# SMS0_TIFS_CBASS_0_CBASS_FW register map
Vendor: Texas Instruments
Peripheral module from a debugger description file (folder am62P).
Registers are 32-bit, read-write, reset 0x0 unless marked. A register's access mark holds for its fields unless they carry their own. Offsets are as the file gives them; lines under a group give offsets from that group; [hi:lo] are bit positions; {n}, {i} and the like mark numbered series; 'fields as' and 'values as' point back to an identical list; <NAME> marks a mode.

## SMS0_TIFS_CBASS_0_CBASS_FW
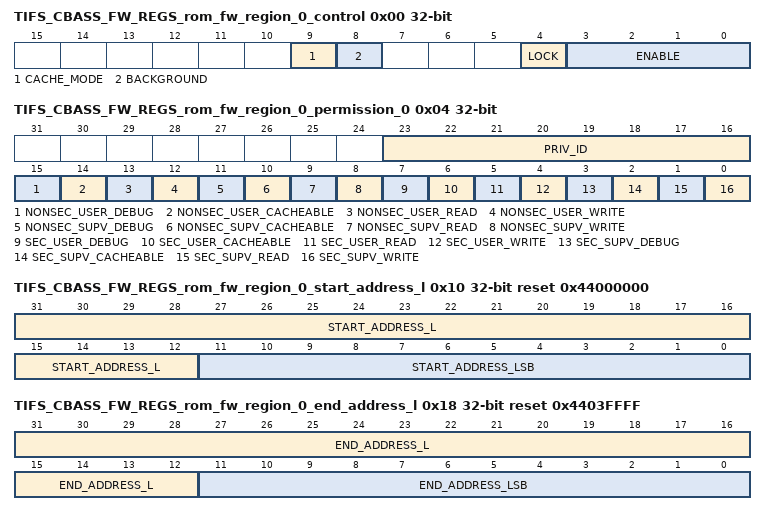
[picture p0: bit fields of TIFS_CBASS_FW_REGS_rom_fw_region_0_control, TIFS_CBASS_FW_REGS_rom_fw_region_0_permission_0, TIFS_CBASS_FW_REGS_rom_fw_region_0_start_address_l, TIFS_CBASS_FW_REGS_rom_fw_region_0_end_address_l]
0x00 TIFS_CBASS_FW_REGS_rom_fw_region_0_control access not given — The FW Region 0 Control Register defines the control fields for the target Irom.slv region 0 firewall.
  [9] CACHE_MODE rw — Cache mode for region. Set to 1 to check cache permissions. Set to 0 to ignore cache permissions.
  [8] BACKGROUND rw — Background enable for region. There can be 1 backgroun region per FW and foreground regions can have overlapping addresses only with the background region.
  [4] LOCK — Lock region. Once set region values cannot be modified. (access R/W1TS)
  [3:0] ENABLE rw — Enable region. A value of 0xA enables, others disable.
0x04 TIFS_CBASS_FW_REGS_rom_fw_region_0_permission_0 — The FW Region 0 Permission 0 Register defines the permissions for the target Irom.slv region 0 firewall.
  [23:16] PRIV_ID — Allowed privid.
  [15] NONSEC_USER_DEBUG — Non-secure user debug allowed.
  [14] NONSEC_USER_CACHEABLE — Non-secure user cacheable allowed.
  [13] NONSEC_USER_READ — Non-secure user read allowed.
  [12] NONSEC_USER_WRITE — Non-secure user write allowed.
  [11] NONSEC_SUPV_DEBUG — Non-secure supervisor debug allowed.
  [10] NONSEC_SUPV_CACHEABLE — Non-secure supervisor cacheable allowed.
  [9] NONSEC_SUPV_READ — Non-secure supervisor read allowed.
  [8] NONSEC_SUPV_WRITE — Non-secure supervisor write allowed.
  [7] SEC_USER_DEBUG — Secure user debug allowed.
  [6] SEC_USER_CACHEABLE — Secure user cacheable allowed.
  [5] SEC_USER_READ — Secure user read allowed.
  [4] SEC_USER_WRITE — Secure user write allowed.
  [3] SEC_SUPV_DEBUG — Secure supervisor debug allowed.
  [2] SEC_SUPV_CACHEABLE — Secure supervisor cacheable allowed.
  [1] SEC_SUPV_READ — Secure supervisor read allowed.
  [0] SEC_SUPV_WRITE — Secure supervisor write allowed.
0x10 TIFS_CBASS_FW_REGS_rom_fw_region_0_start_address_l access per field reset 0x44000000 — The FW Region 0 Start Address Low Register defines the start address bits 31 to 0 for the target Irom.slv region 0 firewall.
  [31:12] START_ADDRESS_L rw — Start address bits 31 to 12. Lowest 12 bits are forced to 0 as address must be 4KB aligned.
  [11:0] START_ADDRESS_LSB ro — Start address bits 11 to 0 are forced to 0 as address must be 4KB aligned.
0x14 TIFS_CBASS_FW_REGS_rom_fw_region_0_start_address_h — The FW Region 0 Start Address High Register defines the start address bits 47 to 32 for the target Irom.slv region 0 firewall.
  [15:0] START_ADDRESS_H — Start address bits 47 to 32.
0x18 TIFS_CBASS_FW_REGS_rom_fw_region_0_end_address_l access per field reset 0x4403FFFF — The FW Region 0 End Address Low Register defines the end address bits 31 to 0 to include for the target Irom.slv region 0 firewall.
  [31:12] END_ADDRESS_L rw — End address bits 31 to 12 to include in the match. Lowest 12 bits are forced to 1s as address must be 4KB aligned.
  [11:0] END_ADDRESS_LSB ro — End address bits 11 to 0 are forced to 1s as address must be 4KB aligned minus 1.
0x1C TIFS_CBASS_FW_REGS_rom_fw_region_0_end_address_h — The FW Region 0 End Address High Register defines the end address bits 47 to 32 to include for the target Irom.slv region 0 firewall.
  [15:0] END_ADDRESS_H — End address bits 47 to 32 to include in the match.
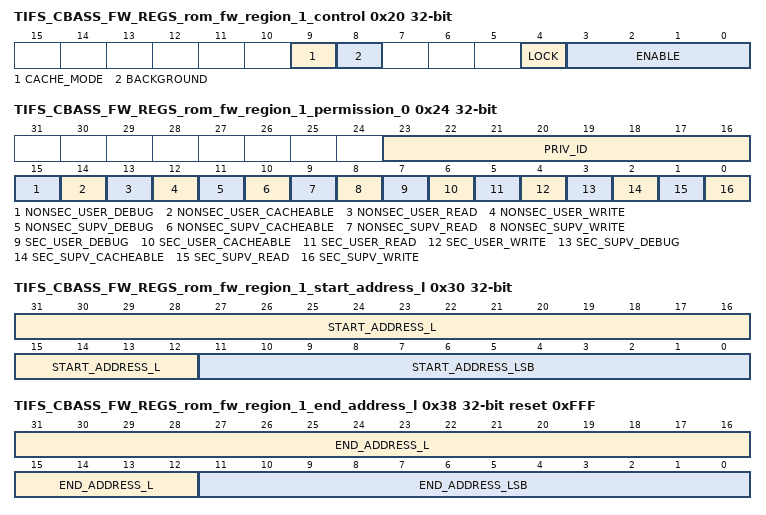
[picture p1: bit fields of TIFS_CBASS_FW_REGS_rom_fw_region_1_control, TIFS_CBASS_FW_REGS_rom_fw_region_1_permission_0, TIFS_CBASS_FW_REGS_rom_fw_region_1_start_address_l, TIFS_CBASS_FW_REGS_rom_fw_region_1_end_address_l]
0x20 TIFS_CBASS_FW_REGS_rom_fw_region_1_control access not given — The FW Region 1 Control Register defines the control fields for the target Irom.slv region 1 firewall.
  fields as TIFS_CBASS_FW_REGS_rom_fw_region_0_control
0x24 TIFS_CBASS_FW_REGS_rom_fw_region_1_permission_0 — The FW Region 1 Permission 0 Register defines the permissions for the target Irom.slv region 1 firewall.
  fields as TIFS_CBASS_FW_REGS_rom_fw_region_0_permission_0
0x30 TIFS_CBASS_FW_REGS_rom_fw_region_1_start_address_l access per field — The FW Region 1 Start Address Low Register defines the start address bits 31 to 0 for the target Irom.slv region 1 firewall.
  fields as TIFS_CBASS_FW_REGS_rom_fw_region_0_start_address_l
0x34 TIFS_CBASS_FW_REGS_rom_fw_region_1_start_address_h — The FW Region 1 Start Address High Register defines the start address bits 47 to 32 for the target Irom.slv region 1 firewall.
  [15:0] START_ADDRESS_H — Start address bits 47 to 32.
0x38 TIFS_CBASS_FW_REGS_rom_fw_region_1_end_address_l access per field reset 0xFFF — The FW Region 1 End Address Low Register defines the end address bits 31 to 0 to include for the target Irom.slv region 1 firewall.
  fields as TIFS_CBASS_FW_REGS_rom_fw_region_0_end_address_l
0x3C TIFS_CBASS_FW_REGS_rom_fw_region_1_end_address_h — The FW Region 1 End Address High Register defines the end address bits 47 to 32 to include for the target Irom.slv region 1 firewall.
  fields as TIFS_CBASS_FW_REGS_rom_fw_region_0_end_address_h
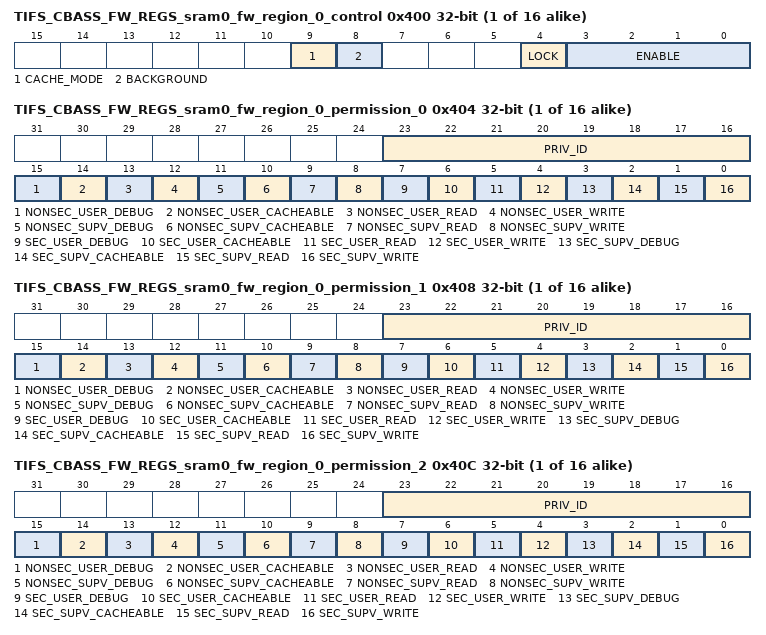
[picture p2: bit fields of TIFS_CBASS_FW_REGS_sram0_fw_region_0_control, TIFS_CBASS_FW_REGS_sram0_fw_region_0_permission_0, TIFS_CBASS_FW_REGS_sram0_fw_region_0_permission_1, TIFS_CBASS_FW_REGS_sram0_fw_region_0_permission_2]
{0x400+0x20*i} TIFS_CBASS_FW_REGS_sram0_fw_region_{i}_control access not given (i=0..15) — The FW Region {i} Control Register defines the control fields for the target Isram0.slv region {i} firewall.
  fields as TIFS_CBASS_FW_REGS_rom_fw_region_0_control
{0x404+0x20*i} TIFS_CBASS_FW_REGS_sram0_fw_region_{i}_permission_0 (i=0..15) — The FW Region {i} Permission 0 Register defines the permissions for the target Isram0.slv region {i} firewall.
  fields as TIFS_CBASS_FW_REGS_rom_fw_region_0_permission_0
{0x408+0x20*i} TIFS_CBASS_FW_REGS_sram0_fw_region_{i}_permission_1 (i=0..15) — The FW Region {i} Permission 1 Register defines the permissions for the target Isram0.slv region {i} firewall.
  fields as TIFS_CBASS_FW_REGS_rom_fw_region_0_permission_0
{0x40C+0x20*i} TIFS_CBASS_FW_REGS_sram0_fw_region_{i}_permission_2 (i=0..15) — The FW Region {i} Permission 2 Register defines the permissions for the target Isram0.slv region {i} firewall.
  fields as TIFS_CBASS_FW_REGS_rom_fw_region_0_permission_0
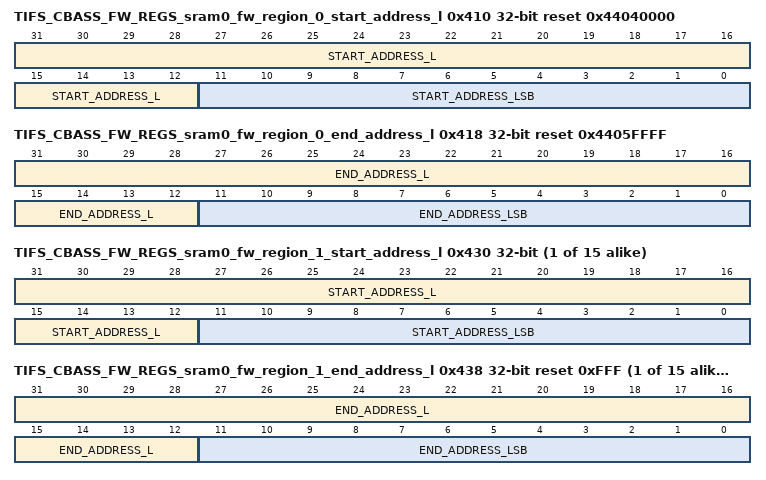
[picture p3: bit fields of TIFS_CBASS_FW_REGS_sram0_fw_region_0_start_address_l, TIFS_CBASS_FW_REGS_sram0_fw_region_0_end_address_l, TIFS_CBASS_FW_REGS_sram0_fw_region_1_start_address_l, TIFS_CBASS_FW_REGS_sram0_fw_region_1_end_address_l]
0x410 TIFS_CBASS_FW_REGS_sram0_fw_region_0_start_address_l access per field reset 0x44040000 — The FW Region 0 Start Address Low Register defines the start address bits 31 to 0 for the target Isram0.slv region 0 firewall.
  fields as TIFS_CBASS_FW_REGS_rom_fw_region_0_start_address_l
{0x414+0x20*i} TIFS_CBASS_FW_REGS_sram0_fw_region_{i}_start_address_h (i=0..15) — The FW Region {i} Start Address High Register defines the start address bits 47 to 32 for the target Isram0.slv region {i} firewall.
  [15:0] START_ADDRESS_H — Start address bits 47 to 32.
0x418 TIFS_CBASS_FW_REGS_sram0_fw_region_0_end_address_l access per field reset 0x4405FFFF — The FW Region 0 End Address Low Register defines the end address bits 31 to 0 to include for the target Isram0.slv region 0 firewall.
  fields as TIFS_CBASS_FW_REGS_rom_fw_region_0_end_address_l
{0x41C+0x20*i} TIFS_CBASS_FW_REGS_sram0_fw_region_{i}_end_address_h (i=0..15) — The FW Region {i} End Address High Register defines the end address bits 47 to 32 to include for the target Isram0.slv region {i} firewall.
  fields as TIFS_CBASS_FW_REGS_rom_fw_region_0_end_address_h
{0x410+0x20*i} TIFS_CBASS_FW_REGS_sram0_fw_region_{i}_start_address_l access per field (i=1..15) — The FW Region {i} Start Address Low Register defines the start address bits 31 to 0 for the target Isram0.slv region {i} firewall.
  fields as TIFS_CBASS_FW_REGS_rom_fw_region_0_start_address_l
{0x418+0x20*i} TIFS_CBASS_FW_REGS_sram0_fw_region_{i}_end_address_l access per field reset 0xFFF (i=1..15) — The FW Region {i} End Address Low Register defines the end address bits 31 to 0 to include for the target Isram0.slv region {i} firewall.
  fields as TIFS_CBASS_FW_REGS_rom_fw_region_0_end_address_l
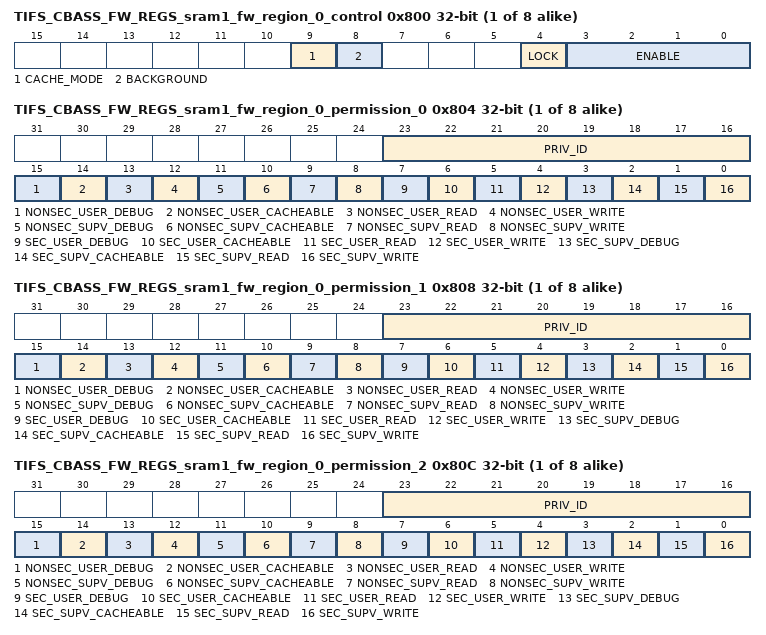
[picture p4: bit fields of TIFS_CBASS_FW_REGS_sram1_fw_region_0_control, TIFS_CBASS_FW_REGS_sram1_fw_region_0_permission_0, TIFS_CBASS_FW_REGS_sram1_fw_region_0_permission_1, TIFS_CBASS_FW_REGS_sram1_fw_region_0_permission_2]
{0x800+0x20*i} TIFS_CBASS_FW_REGS_sram1_fw_region_{i}_control access not given (i=0..7) — The FW Region {i} Control Register defines the control fields for the target Isram1.slv region {i} firewall.
  fields as TIFS_CBASS_FW_REGS_rom_fw_region_0_control
{0x804+0x20*i} TIFS_CBASS_FW_REGS_sram1_fw_region_{i}_permission_0 (i=0..7) — The FW Region {i} Permission 0 Register defines the permissions for the target Isram1.slv region {i} firewall.
  fields as TIFS_CBASS_FW_REGS_rom_fw_region_0_permission_0
{0x808+0x20*i} TIFS_CBASS_FW_REGS_sram1_fw_region_{i}_permission_1 (i=0..7) — The FW Region {i} Permission 1 Register defines the permissions for the target Isram1.slv region {i} firewall.
  fields as TIFS_CBASS_FW_REGS_rom_fw_region_0_permission_0
{0x80C+0x20*i} TIFS_CBASS_FW_REGS_sram1_fw_region_{i}_permission_2 (i=0..7) — The FW Region {i} Permission 2 Register defines the permissions for the target Isram1.slv region {i} firewall.
  fields as TIFS_CBASS_FW_REGS_rom_fw_region_0_permission_0
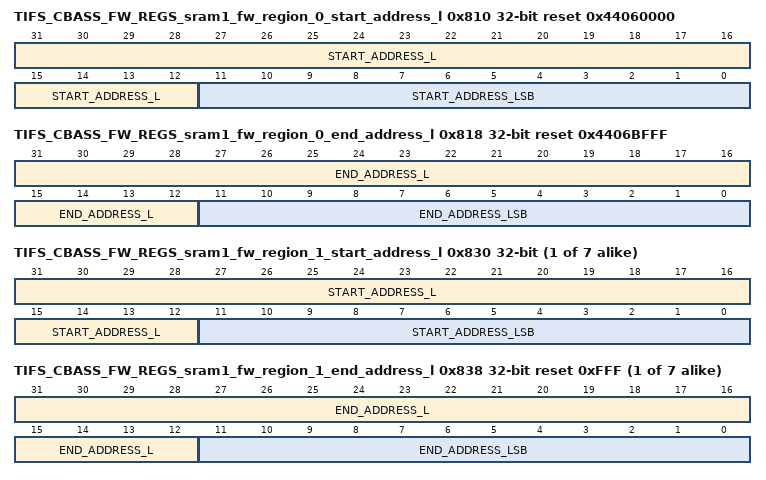
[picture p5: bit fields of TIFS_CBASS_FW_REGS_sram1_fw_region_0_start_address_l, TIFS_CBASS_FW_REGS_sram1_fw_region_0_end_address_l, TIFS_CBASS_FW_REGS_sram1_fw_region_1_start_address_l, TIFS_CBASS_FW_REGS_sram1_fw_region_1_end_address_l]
0x810 TIFS_CBASS_FW_REGS_sram1_fw_region_0_start_address_l access per field reset 0x44060000 — The FW Region 0 Start Address Low Register defines the start address bits 31 to 0 for the target Isram1.slv region 0 firewall.
  fields as TIFS_CBASS_FW_REGS_rom_fw_region_0_start_address_l
{0x814+0x20*i} TIFS_CBASS_FW_REGS_sram1_fw_region_{i}_start_address_h (i=0..7) — The FW Region {i} Start Address High Register defines the start address bits 47 to 32 for the target Isram1.slv region {i} firewall.
  [15:0] START_ADDRESS_H — Start address bits 47 to 32.
0x818 TIFS_CBASS_FW_REGS_sram1_fw_region_0_end_address_l access per field reset 0x4406BFFF — The FW Region 0 End Address Low Register defines the end address bits 31 to 0 to include for the target Isram1.slv region 0 firewall.
  fields as TIFS_CBASS_FW_REGS_rom_fw_region_0_end_address_l
{0x81C+0x20*i} TIFS_CBASS_FW_REGS_sram1_fw_region_{i}_end_address_h (i=0..7) — The FW Region {i} End Address High Register defines the end address bits 47 to 32 to include for the target Isram1.slv region {i} firewall.
  fields as TIFS_CBASS_FW_REGS_rom_fw_region_0_end_address_h
{0x810+0x20*i} TIFS_CBASS_FW_REGS_sram1_fw_region_{i}_start_address_l access per field (i=1..7) — The FW Region {i} Start Address Low Register defines the start address bits 31 to 0 for the target Isram1.slv region {i} firewall.
  fields as TIFS_CBASS_FW_REGS_rom_fw_region_0_start_address_l
{0x818+0x20*i} TIFS_CBASS_FW_REGS_sram1_fw_region_{i}_end_address_l access per field reset 0xFFF (i=1..7) — The FW Region {i} End Address Low Register defines the end address bits 31 to 0 to include for the target Isram1.slv region {i} firewall.
  fields as TIFS_CBASS_FW_REGS_rom_fw_region_0_end_address_l
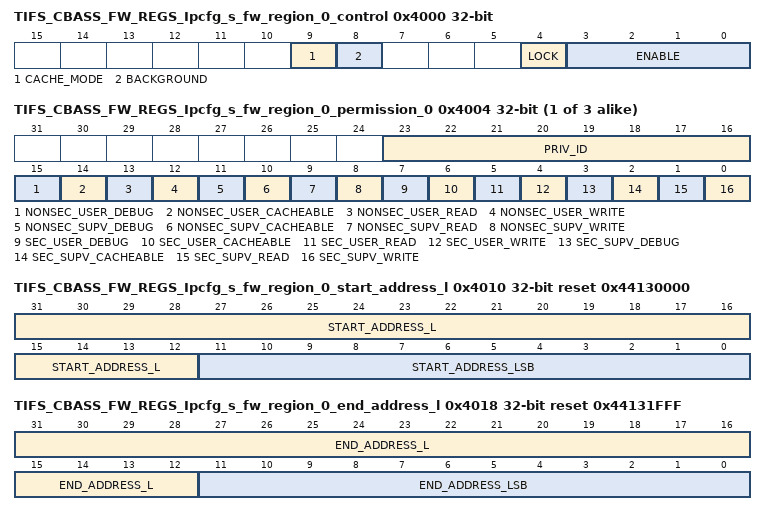
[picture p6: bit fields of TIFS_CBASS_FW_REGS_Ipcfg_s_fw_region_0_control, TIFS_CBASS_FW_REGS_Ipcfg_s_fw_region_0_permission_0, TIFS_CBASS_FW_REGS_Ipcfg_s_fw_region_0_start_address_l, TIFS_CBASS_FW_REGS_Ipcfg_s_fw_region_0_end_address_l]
0x4000 TIFS_CBASS_FW_REGS_Ipcfg_s_fw_region_0_control access not given — The FW Region 0 Control Register defines the control fields for the target Ipcfg.slv region 0 firewall.
  fields as TIFS_CBASS_FW_REGS_rom_fw_region_0_control
{0x4004+4i} TIFS_CBASS_FW_REGS_Ipcfg_s_fw_region_0_permission_{i} (i=0..2) — The FW Region 0 Permission {i} Register defines the permissions for the target Ipcfg.slv region 0 firewall.
  fields as TIFS_CBASS_FW_REGS_rom_fw_region_0_permission_0
0x4010 TIFS_CBASS_FW_REGS_Ipcfg_s_fw_region_0_start_address_l access per field reset 0x44130000 — The FW Region 0 Start Address Low Register defines the start address bits 31 to 0 for the target Ipcfg.slv region 0 firewall.
  fields as TIFS_CBASS_FW_REGS_rom_fw_region_0_start_address_l
0x4014 TIFS_CBASS_FW_REGS_Ipcfg_s_fw_region_0_start_address_h — The FW Region 0 Start Address High Register defines the start address bits 47 to 32 for the target Ipcfg.slv region 0 firewall.
  [15:0] START_ADDRESS_H — Start address bits 47 to 32.
0x4018 TIFS_CBASS_FW_REGS_Ipcfg_s_fw_region_0_end_address_l access per field reset 0x44131FFF — The FW Region 0 End Address Low Register defines the end address bits 31 to 0 to include for the target Ipcfg.slv region 0 firewall.
  fields as TIFS_CBASS_FW_REGS_rom_fw_region_0_end_address_l
0x401C TIFS_CBASS_FW_REGS_Ipcfg_s_fw_region_0_end_address_h — The FW Region 0 End Address High Register defines the end address bits 47 to 32 to include for the target Ipcfg.slv region 0 firewall.
  fields as TIFS_CBASS_FW_REGS_rom_fw_region_0_end_address_h
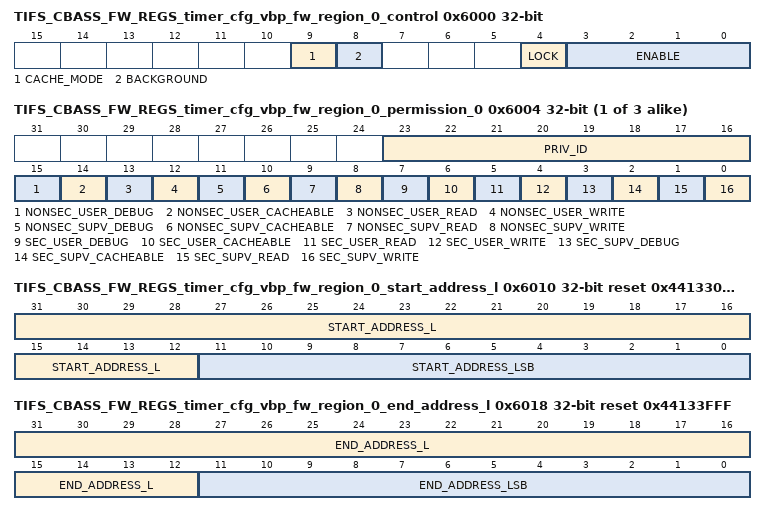
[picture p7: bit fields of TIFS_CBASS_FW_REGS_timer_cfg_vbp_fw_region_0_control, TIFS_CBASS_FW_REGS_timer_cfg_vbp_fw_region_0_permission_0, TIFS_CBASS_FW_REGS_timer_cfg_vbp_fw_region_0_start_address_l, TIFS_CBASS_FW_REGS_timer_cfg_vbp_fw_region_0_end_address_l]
0x6000 TIFS_CBASS_FW_REGS_timer_cfg_vbp_fw_region_0_control access not given — The FW Region 0 Control Register defines the control fields for the target Itimer1.timer_cfg_vbp region 0 firewall.
  fields as TIFS_CBASS_FW_REGS_rom_fw_region_0_control
{0x6004+4i} TIFS_CBASS_FW_REGS_timer_cfg_vbp_fw_region_0_permission_{i} (i=0..2) — The FW Region 0 Permission {i} Register defines the permissions for the target Itimer1.timer_cfg_vbp region 0 firewall.
  fields as TIFS_CBASS_FW_REGS_rom_fw_region_0_permission_0
0x6010 TIFS_CBASS_FW_REGS_timer_cfg_vbp_fw_region_0_start_address_l access per field reset 0x44133000 — The FW Region 0 Start Address Low Register defines the start address bits 31 to 0 for the target Itimer1.timer_cfg_vbp region 0 firewall.
  fields as TIFS_CBASS_FW_REGS_rom_fw_region_0_start_address_l
0x6014 TIFS_CBASS_FW_REGS_timer_cfg_vbp_fw_region_0_start_address_h — The FW Region 0 Start Address High Register defines the start address bits 47 to 32 for the target Itimer1.timer_cfg_vbp region 0 firewall.
  [15:0] START_ADDRESS_H — Start address bits 47 to 32.
0x6018 TIFS_CBASS_FW_REGS_timer_cfg_vbp_fw_region_0_end_address_l access per field reset 0x44133FFF — The FW Region 0 End Address Low Register defines the end address bits 31 to 0 to include for the target Itimer1.timer_cfg_vbp region 0 firewall.
  fields as TIFS_CBASS_FW_REGS_rom_fw_region_0_end_address_l
0x601C TIFS_CBASS_FW_REGS_timer_cfg_vbp_fw_region_0_end_address_h — The FW Region 0 End Address High Register defines the end address bits 47 to 32 to include for the target Itimer1.timer_cfg_vbp region 0 firewall.
  fields as TIFS_CBASS_FW_REGS_rom_fw_region_0_end_address_h
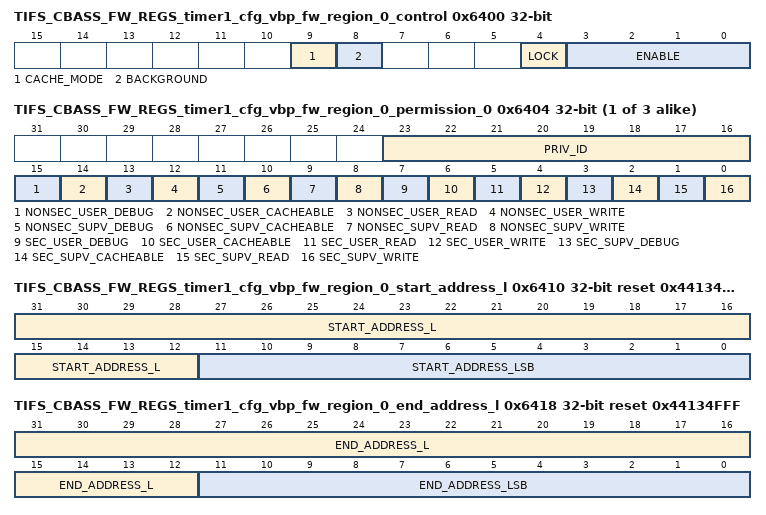
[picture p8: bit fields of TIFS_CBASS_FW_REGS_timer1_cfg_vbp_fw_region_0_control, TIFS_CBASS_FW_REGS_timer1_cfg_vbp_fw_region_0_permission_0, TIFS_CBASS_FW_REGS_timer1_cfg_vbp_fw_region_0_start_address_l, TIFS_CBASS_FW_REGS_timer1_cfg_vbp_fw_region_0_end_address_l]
0x6400 TIFS_CBASS_FW_REGS_timer1_cfg_vbp_fw_region_0_control access not given — The FW Region 0 Control Register defines the control fields for the target Itimer2.timer_cfg_vbp region 0 firewall.
  fields as TIFS_CBASS_FW_REGS_rom_fw_region_0_control
{0x6404+4i} TIFS_CBASS_FW_REGS_timer1_cfg_vbp_fw_region_0_permission_{i} (i=0..2) — The FW Region 0 Permission {i} Register defines the permissions for the target Itimer2.timer_cfg_vbp region 0 firewall.
  fields as TIFS_CBASS_FW_REGS_rom_fw_region_0_permission_0
0x6410 TIFS_CBASS_FW_REGS_timer1_cfg_vbp_fw_region_0_start_address_l access per field reset 0x44134000 — The FW Region 0 Start Address Low Register defines the start address bits 31 to 0 for the target Itimer2.timer_cfg_vbp region 0 firewall.
  fields as TIFS_CBASS_FW_REGS_rom_fw_region_0_start_address_l
0x6414 TIFS_CBASS_FW_REGS_timer1_cfg_vbp_fw_region_0_start_address_h — The FW Region 0 Start Address High Register defines the start address bits 47 to 32 for the target Itimer2.timer_cfg_vbp region 0 firewall.
  [15:0] START_ADDRESS_H — Start address bits 47 to 32.
0x6418 TIFS_CBASS_FW_REGS_timer1_cfg_vbp_fw_region_0_end_address_l access per field reset 0x44134FFF — The FW Region 0 End Address Low Register defines the end address bits 31 to 0 to include for the target Itimer2.timer_cfg_vbp region 0 firewall.
  fields as TIFS_CBASS_FW_REGS_rom_fw_region_0_end_address_l
0x641C TIFS_CBASS_FW_REGS_timer1_cfg_vbp_fw_region_0_end_address_h — The FW Region 0 End Address High Register defines the end address bits 47 to 32 to include for the target Itimer2.timer_cfg_vbp region 0 firewall.
  fields as TIFS_CBASS_FW_REGS_rom_fw_region_0_end_address_h
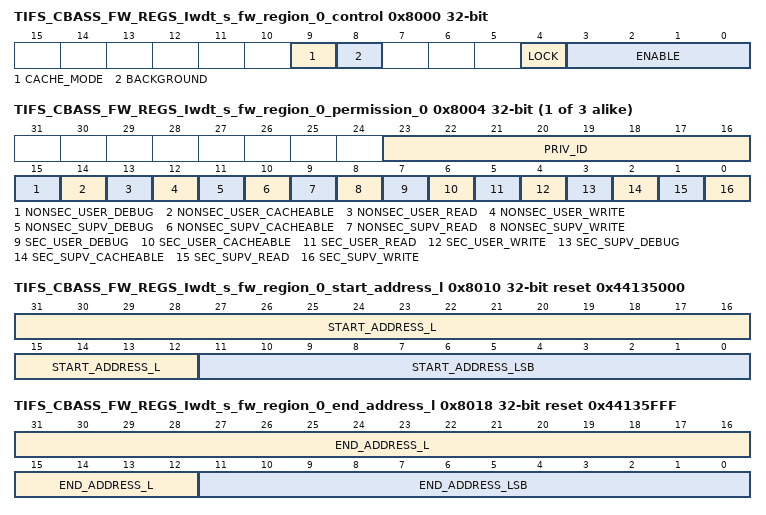
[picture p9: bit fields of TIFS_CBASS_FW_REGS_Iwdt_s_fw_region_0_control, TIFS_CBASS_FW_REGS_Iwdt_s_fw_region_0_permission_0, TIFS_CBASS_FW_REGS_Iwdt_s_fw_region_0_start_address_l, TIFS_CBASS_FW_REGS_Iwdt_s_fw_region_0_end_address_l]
0x8000 TIFS_CBASS_FW_REGS_Iwdt_s_fw_region_0_control access not given — The FW Region 0 Control Register defines the control fields for the target Iwdt.slv region 0 firewall.
  fields as TIFS_CBASS_FW_REGS_rom_fw_region_0_control
{0x8004+4i} TIFS_CBASS_FW_REGS_Iwdt_s_fw_region_0_permission_{i} (i=0..2) — The FW Region 0 Permission {i} Register defines the permissions for the target Iwdt.slv region 0 firewall.
  fields as TIFS_CBASS_FW_REGS_rom_fw_region_0_permission_0
0x8010 TIFS_CBASS_FW_REGS_Iwdt_s_fw_region_0_start_address_l access per field reset 0x44135000 — The FW Region 0 Start Address Low Register defines the start address bits 31 to 0 for the target Iwdt.slv region 0 firewall.
  fields as TIFS_CBASS_FW_REGS_rom_fw_region_0_start_address_l
0x8014 TIFS_CBASS_FW_REGS_Iwdt_s_fw_region_0_start_address_h — The FW Region 0 Start Address High Register defines the start address bits 47 to 32 for the target Iwdt.slv region 0 firewall.
  [15:0] START_ADDRESS_H — Start address bits 47 to 32.
0x8018 TIFS_CBASS_FW_REGS_Iwdt_s_fw_region_0_end_address_l access per field reset 0x44135FFF — The FW Region 0 End Address Low Register defines the end address bits 31 to 0 to include for the target Iwdt.slv region 0 firewall.
  fields as TIFS_CBASS_FW_REGS_rom_fw_region_0_end_address_l
0x801C TIFS_CBASS_FW_REGS_Iwdt_s_fw_region_0_end_address_h — The FW Region 0 End Address High Register defines the end address bits 47 to 32 to include for the target Iwdt.slv region 0 firewall.
  fields as TIFS_CBASS_FW_REGS_rom_fw_region_0_end_address_h
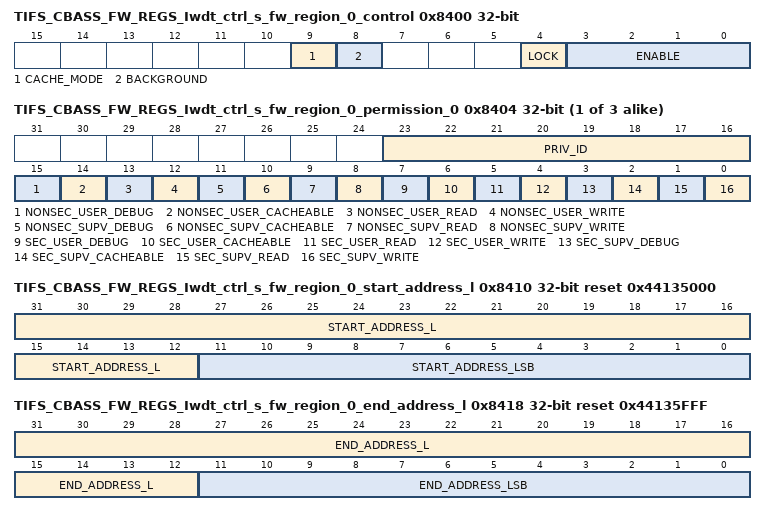
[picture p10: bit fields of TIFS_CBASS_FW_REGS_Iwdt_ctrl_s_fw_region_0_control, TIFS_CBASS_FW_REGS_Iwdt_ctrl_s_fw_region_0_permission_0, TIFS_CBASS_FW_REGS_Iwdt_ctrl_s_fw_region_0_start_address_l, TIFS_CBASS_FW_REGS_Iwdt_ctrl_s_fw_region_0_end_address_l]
0x8400 TIFS_CBASS_FW_REGS_Iwdt_ctrl_s_fw_region_0_control access not given — The FW Region 0 Control Register defines the control fields for the target Iwdt_ctrl.slv region 0 firewall.
  fields as TIFS_CBASS_FW_REGS_rom_fw_region_0_control
{0x8404+4i} TIFS_CBASS_FW_REGS_Iwdt_ctrl_s_fw_region_0_permission_{i} (i=0..2) — The FW Region 0 Permission {i} Register defines the permissions for the target Iwdt_ctrl.slv region 0 firewall.
  fields as TIFS_CBASS_FW_REGS_rom_fw_region_0_permission_0
0x8410 TIFS_CBASS_FW_REGS_Iwdt_ctrl_s_fw_region_0_start_address_l access per field reset 0x44135000 — The FW Region 0 Start Address Low Register defines the start address bits 31 to 0 for the target Iwdt_ctrl.slv region 0 firewall.
  fields as TIFS_CBASS_FW_REGS_rom_fw_region_0_start_address_l
0x8414 TIFS_CBASS_FW_REGS_Iwdt_ctrl_s_fw_region_0_start_address_h — The FW Region 0 Start Address High Register defines the start address bits 47 to 32 for the target Iwdt_ctrl.slv region 0 firewall.
  [15:0] START_ADDRESS_H — Start address bits 47 to 32.
0x8418 TIFS_CBASS_FW_REGS_Iwdt_ctrl_s_fw_region_0_end_address_l access per field reset 0x44135FFF — The FW Region 0 End Address Low Register defines the end address bits 31 to 0 to include for the target Iwdt_ctrl.slv region 0 firewall.
  fields as TIFS_CBASS_FW_REGS_rom_fw_region_0_end_address_l
0x841C TIFS_CBASS_FW_REGS_Iwdt_ctrl_s_fw_region_0_end_address_h — The FW Region 0 End Address High Register defines the end address bits 47 to 32 to include for the target Iwdt_ctrl.slv region 0 firewall.
  fields as TIFS_CBASS_FW_REGS_rom_fw_region_0_end_address_h
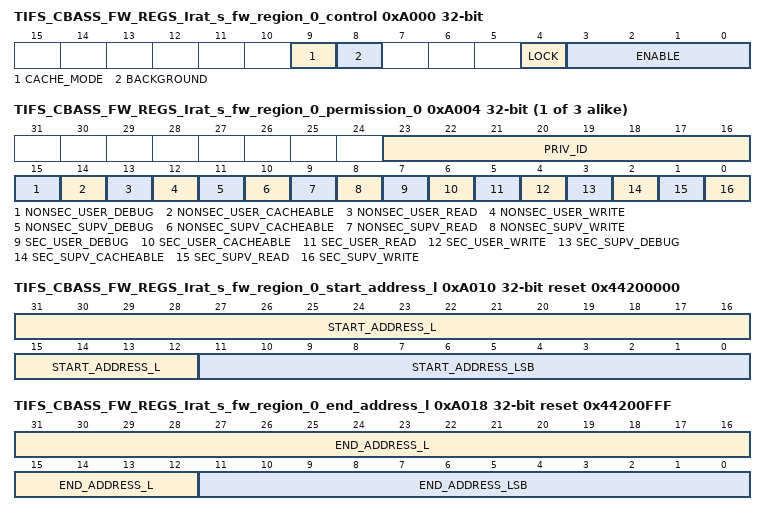
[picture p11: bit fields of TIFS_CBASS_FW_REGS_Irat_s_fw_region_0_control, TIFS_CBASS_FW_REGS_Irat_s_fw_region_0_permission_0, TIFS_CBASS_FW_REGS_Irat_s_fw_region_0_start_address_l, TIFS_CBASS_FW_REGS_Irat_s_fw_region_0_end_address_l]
0xA000 TIFS_CBASS_FW_REGS_Irat_s_fw_region_0_control access not given — The FW Region 0 Control Register defines the control fields for the target Irat.slv region 0 firewall.
  fields as TIFS_CBASS_FW_REGS_rom_fw_region_0_control
{0xA004+4i} TIFS_CBASS_FW_REGS_Irat_s_fw_region_0_permission_{i} (i=0..2) — The FW Region 0 Permission {i} Register defines the permissions for the target Irat.slv region 0 firewall.
  fields as TIFS_CBASS_FW_REGS_rom_fw_region_0_permission_0
0xA010 TIFS_CBASS_FW_REGS_Irat_s_fw_region_0_start_address_l access per field reset 0x44200000 — The FW Region 0 Start Address Low Register defines the start address bits 31 to 0 for the target Irat.slv region 0 firewall.
  fields as TIFS_CBASS_FW_REGS_rom_fw_region_0_start_address_l
0xA014 TIFS_CBASS_FW_REGS_Irat_s_fw_region_0_start_address_h — The FW Region 0 Start Address High Register defines the start address bits 47 to 32 for the target Irat.slv region 0 firewall.
  [15:0] START_ADDRESS_H — Start address bits 47 to 32.
0xA018 TIFS_CBASS_FW_REGS_Irat_s_fw_region_0_end_address_l access per field reset 0x44200FFF — The FW Region 0 End Address Low Register defines the end address bits 31 to 0 to include for the target Irat.slv region 0 firewall.
  fields as TIFS_CBASS_FW_REGS_rom_fw_region_0_end_address_l
0xA01C TIFS_CBASS_FW_REGS_Irat_s_fw_region_0_end_address_h — The FW Region 0 End Address High Register defines the end address bits 47 to 32 to include for the target Irat.slv region 0 firewall.
  fields as TIFS_CBASS_FW_REGS_rom_fw_region_0_end_address_h
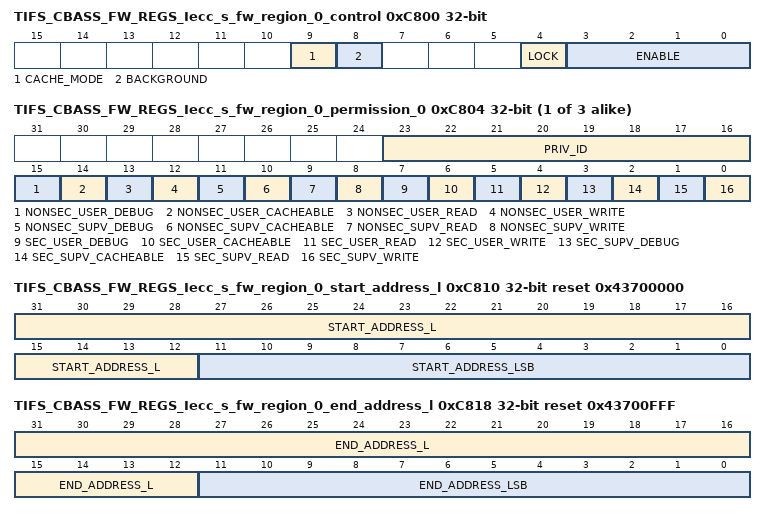
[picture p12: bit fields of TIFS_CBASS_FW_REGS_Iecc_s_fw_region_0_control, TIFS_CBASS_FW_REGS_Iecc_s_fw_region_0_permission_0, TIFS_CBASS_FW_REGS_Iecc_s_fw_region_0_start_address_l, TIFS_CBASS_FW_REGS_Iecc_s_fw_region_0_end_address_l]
0xC800 TIFS_CBASS_FW_REGS_Iecc_s_fw_region_0_control access not given — The FW Region 0 Control Register defines the control fields for the target Iecc.cfg region 0 firewall.
  fields as TIFS_CBASS_FW_REGS_rom_fw_region_0_control
{0xC804+4i} TIFS_CBASS_FW_REGS_Iecc_s_fw_region_0_permission_{i} (i=0..2) — The FW Region 0 Permission {i} Register defines the permissions for the target Iecc.cfg region 0 firewall.
  fields as TIFS_CBASS_FW_REGS_rom_fw_region_0_permission_0
0xC810 TIFS_CBASS_FW_REGS_Iecc_s_fw_region_0_start_address_l access per field reset 0x43700000 — The FW Region 0 Start Address Low Register defines the start address bits 31 to 0 for the target Iecc.cfg region 0 firewall.
  fields as TIFS_CBASS_FW_REGS_rom_fw_region_0_start_address_l
0xC814 TIFS_CBASS_FW_REGS_Iecc_s_fw_region_0_start_address_h — The FW Region 0 Start Address High Register defines the start address bits 47 to 32 for the target Iecc.cfg region 0 firewall.
  [15:0] START_ADDRESS_H — Start address bits 47 to 32.
0xC818 TIFS_CBASS_FW_REGS_Iecc_s_fw_region_0_end_address_l access per field reset 0x43700FFF — The FW Region 0 End Address Low Register defines the end address bits 31 to 0 to include for the target Iecc.cfg region 0 firewall.
  fields as TIFS_CBASS_FW_REGS_rom_fw_region_0_end_address_l
0xC81C TIFS_CBASS_FW_REGS_Iecc_s_fw_region_0_end_address_h — The FW Region 0 End Address High Register defines the end address bits 47 to 32 to include for the target Iecc.cfg region 0 firewall.
  fields as TIFS_CBASS_FW_REGS_rom_fw_region_0_end_address_h
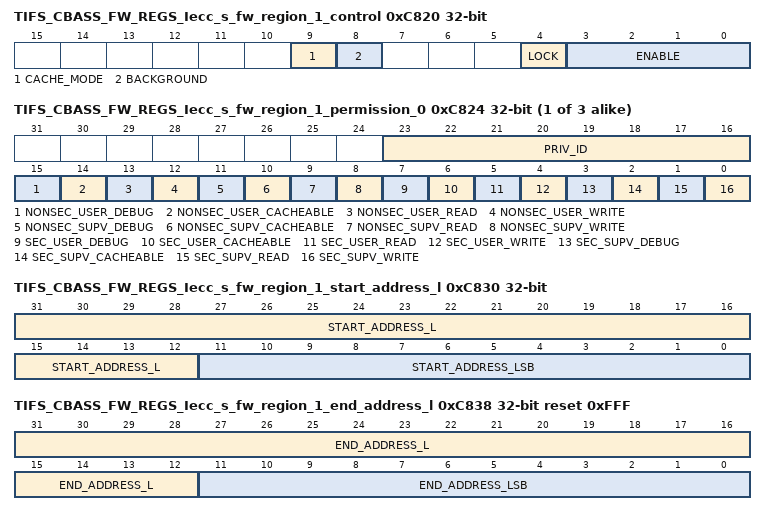
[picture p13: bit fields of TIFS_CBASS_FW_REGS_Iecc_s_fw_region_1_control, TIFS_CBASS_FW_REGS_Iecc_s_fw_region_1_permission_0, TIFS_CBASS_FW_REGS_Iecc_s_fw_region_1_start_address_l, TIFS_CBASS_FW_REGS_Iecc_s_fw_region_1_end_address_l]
0xC820 TIFS_CBASS_FW_REGS_Iecc_s_fw_region_1_control access not given — The FW Region 1 Control Register defines the control fields for the target Iecc.cfg region 1 firewall.
  fields as TIFS_CBASS_FW_REGS_rom_fw_region_0_control
{0xC824+4i} TIFS_CBASS_FW_REGS_Iecc_s_fw_region_1_permission_{i} (i=0..2) — The FW Region 1 Permission {i} Register defines the permissions for the target Iecc.cfg region 1 firewall.
  fields as TIFS_CBASS_FW_REGS_rom_fw_region_0_permission_0
0xC830 TIFS_CBASS_FW_REGS_Iecc_s_fw_region_1_start_address_l access per field — The FW Region 1 Start Address Low Register defines the start address bits 31 to 0 for the target Iecc.cfg region 1 firewall.
  fields as TIFS_CBASS_FW_REGS_rom_fw_region_0_start_address_l
0xC834 TIFS_CBASS_FW_REGS_Iecc_s_fw_region_1_start_address_h — The FW Region 1 Start Address High Register defines the start address bits 47 to 32 for the target Iecc.cfg region 1 firewall.
  [15:0] START_ADDRESS_H — Start address bits 47 to 32.
0xC838 TIFS_CBASS_FW_REGS_Iecc_s_fw_region_1_end_address_l access per field reset 0xFFF — The FW Region 1 End Address Low Register defines the end address bits 31 to 0 to include for the target Iecc.cfg region 1 firewall.
  fields as TIFS_CBASS_FW_REGS_rom_fw_region_0_end_address_l
0xC83C TIFS_CBASS_FW_REGS_Iecc_s_fw_region_1_end_address_h — The FW Region 1 End Address High Register defines the end address bits 47 to 32 to include for the target Iecc.cfg region 1 firewall.
  fields as TIFS_CBASS_FW_REGS_rom_fw_region_0_end_address_h
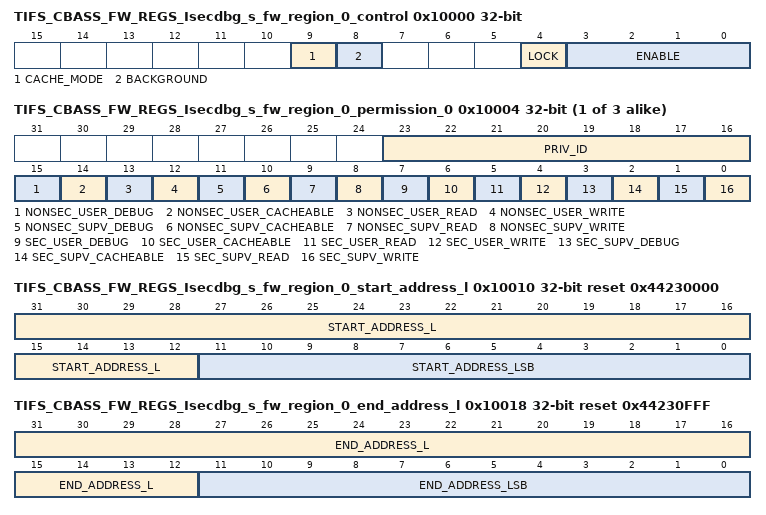
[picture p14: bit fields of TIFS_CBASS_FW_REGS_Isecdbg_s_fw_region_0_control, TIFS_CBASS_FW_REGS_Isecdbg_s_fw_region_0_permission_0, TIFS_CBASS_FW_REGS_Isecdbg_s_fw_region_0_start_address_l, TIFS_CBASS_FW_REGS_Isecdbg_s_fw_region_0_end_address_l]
0x10000 TIFS_CBASS_FW_REGS_Isecdbg_s_fw_region_0_control access not given — The FW Region 0 Control Register defines the control fields for the target Isecdbg.slv region 0 firewall.
  fields as TIFS_CBASS_FW_REGS_rom_fw_region_0_control
{0x10004+4i} TIFS_CBASS_FW_REGS_Isecdbg_s_fw_region_0_permission_{i} (i=0..2) — The FW Region 0 Permission {i} Register defines the permissions for the target Isecdbg.slv region 0 firewall.
  fields as TIFS_CBASS_FW_REGS_rom_fw_region_0_permission_0
0x10010 TIFS_CBASS_FW_REGS_Isecdbg_s_fw_region_0_start_address_l access per field reset 0x44230000 — The FW Region 0 Start Address Low Register defines the start address bits 31 to 0 for the target Isecdbg.slv region 0 firewall.
  fields as TIFS_CBASS_FW_REGS_rom_fw_region_0_start_address_l
0x10014 TIFS_CBASS_FW_REGS_Isecdbg_s_fw_region_0_start_address_h — The FW Region 0 Start Address High Register defines the start address bits 47 to 32 for the target Isecdbg.slv region 0 firewall.
  [15:0] START_ADDRESS_H — Start address bits 47 to 32.
0x10018 TIFS_CBASS_FW_REGS_Isecdbg_s_fw_region_0_end_address_l access per field reset 0x44230FFF — The FW Region 0 End Address Low Register defines the end address bits 31 to 0 to include for the target Isecdbg.slv region 0 firewall.
  fields as TIFS_CBASS_FW_REGS_rom_fw_region_0_end_address_l
0x1001C TIFS_CBASS_FW_REGS_Isecdbg_s_fw_region_0_end_address_h — The FW Region 0 End Address High Register defines the end address bits 47 to 32 to include for the target Isecdbg.slv region 0 firewall.
  fields as TIFS_CBASS_FW_REGS_rom_fw_region_0_end_address_h
0x10800 TIFS_CBASS_FW_REGS_Idbg_auth_s_fw_region_0_control access not given — The FW Region 0 Control Register defines the control fields for the target Idbg_auth.slv region 0 firewall.
  fields as TIFS_CBASS_FW_REGS_rom_fw_region_0_control
{0x10804+4i} TIFS_CBASS_FW_REGS_Idbg_auth_s_fw_region_0_permission_{i} (i=0..2) — The FW Region 0 Permission {i} Register defines the permissions for the target Idbg_auth.slv region 0 firewall.
  fields as TIFS_CBASS_FW_REGS_rom_fw_region_0_permission_0
0x10810 TIFS_CBASS_FW_REGS_Idbg_auth_s_fw_region_0_start_address_l access per field reset 0x44232000 — The FW Region 0 Start Address Low Register defines the start address bits 31 to 0 for the target Idbg_auth.slv region 0 firewall.
  fields as TIFS_CBASS_FW_REGS_rom_fw_region_0_start_address_l
0x10814 TIFS_CBASS_FW_REGS_Idbg_auth_s_fw_region_0_start_address_h — The FW Region 0 Start Address High Register defines the start address bits 47 to 32 for the target Idbg_auth.slv region 0 firewall.
  [15:0] START_ADDRESS_H — Start address bits 47 to 32.
0x10818 TIFS_CBASS_FW_REGS_Idbg_auth_s_fw_region_0_end_address_l access per field reset 0x44232FFF — The FW Region 0 End Address Low Register defines the end address bits 31 to 0 to include for the target Idbg_auth.slv region 0 firewall.
  fields as TIFS_CBASS_FW_REGS_rom_fw_region_0_end_address_l
0x1081C TIFS_CBASS_FW_REGS_Idbg_auth_s_fw_region_0_end_address_h — The FW Region 0 End Address High Register defines the end address bits 47 to 32 to include for the target Idbg_auth.slv region 0 firewall.
  fields as TIFS_CBASS_FW_REGS_rom_fw_region_0_end_address_h
0x11800 TIFS_CBASS_FW_REGS_Iseckey_s_fw_region_0_control access not given — The FW Region 0 Control Register defines the control fields for the target Iseckey.slv region 0 firewall.
  fields as TIFS_CBASS_FW_REGS_rom_fw_region_0_control
{0x11804+4i} TIFS_CBASS_FW_REGS_Iseckey_s_fw_region_0_permission_{i} (i=0..2) — The FW Region 0 Permission {i} Register defines the permissions for the target Iseckey.slv region 0 firewall.
  fields as TIFS_CBASS_FW_REGS_rom_fw_region_0_permission_0
0x11810 TIFS_CBASS_FW_REGS_Iseckey_s_fw_region_0_start_address_l access per field reset 0x44234000 — The FW Region 0 Start Address Low Register defines the start address bits 31 to 0 for the target Iseckey.slv region 0 firewall.
  fields as TIFS_CBASS_FW_REGS_rom_fw_region_0_start_address_l
0x11814 TIFS_CBASS_FW_REGS_Iseckey_s_fw_region_0_start_address_h — The FW Region 0 Start Address High Register defines the start address bits 47 to 32 for the target Iseckey.slv region 0 firewall.
  [15:0] START_ADDRESS_H — Start address bits 47 to 32.
0x11818 TIFS_CBASS_FW_REGS_Iseckey_s_fw_region_0_end_address_l access per field reset 0x44237FFF — The FW Region 0 End Address Low Register defines the end address bits 31 to 0 to include for the target Iseckey.slv region 0 firewall.
  fields as TIFS_CBASS_FW_REGS_rom_fw_region_0_end_address_l
0x1181C TIFS_CBASS_FW_REGS_Iseckey_s_fw_region_0_end_address_h — The FW Region 0 End Address High Register defines the end address bits 47 to 32 to include for the target Iseckey.slv region 0 firewall.
  fields as TIFS_CBASS_FW_REGS_rom_fw_region_0_end_address_h
0x11820 TIFS_CBASS_FW_REGS_Iseckey_s_fw_region_1_control access not given — The FW Region 1 Control Register defines the control fields for the target Iseckey.slv region 1 firewall.
  fields as TIFS_CBASS_FW_REGS_rom_fw_region_0_control
{0x11824+4i} TIFS_CBASS_FW_REGS_Iseckey_s_fw_region_1_permission_{i} (i=0..2) — The FW Region 1 Permission {i} Register defines the permissions for the target Iseckey.slv region 1 firewall.
  fields as TIFS_CBASS_FW_REGS_rom_fw_region_0_permission_0
0x11830 TIFS_CBASS_FW_REGS_Iseckey_s_fw_region_1_start_address_l access per field — The FW Region 1 Start Address Low Register defines the start address bits 31 to 0 for the target Iseckey.slv region 1 firewall.
  fields as TIFS_CBASS_FW_REGS_rom_fw_region_0_start_address_l
0x11834 TIFS_CBASS_FW_REGS_Iseckey_s_fw_region_1_start_address_h — The FW Region 1 Start Address High Register defines the start address bits 47 to 32 for the target Iseckey.slv region 1 firewall.
  [15:0] START_ADDRESS_H — Start address bits 47 to 32.
0x11838 TIFS_CBASS_FW_REGS_Iseckey_s_fw_region_1_end_address_l access per field reset 0xFFF — The FW Region 1 End Address Low Register defines the end address bits 31 to 0 to include for the target Iseckey.slv region 1 firewall.
  fields as TIFS_CBASS_FW_REGS_rom_fw_region_0_end_address_l
0x1183C TIFS_CBASS_FW_REGS_Iseckey_s_fw_region_1_end_address_h — The FW Region 1 End Address High Register defines the end address bits 47 to 32 to include for the target Iseckey.slv region 1 firewall.
  fields as TIFS_CBASS_FW_REGS_rom_fw_region_0_end_address_h
0x14000 TIFS_CBASS_FW_REGS_timer2_cfg_vbp_fw_region_0_control access not given — The FW Region 0 Control Register defines the control fields for the target Itimer3.timer_cfg_vbp region 0 firewall.
  fields as TIFS_CBASS_FW_REGS_rom_fw_region_0_control
{0x14004+4i} TIFS_CBASS_FW_REGS_timer2_cfg_vbp_fw_region_0_permission_{i} (i=0..2) — The FW Region 0 Permission {i} Register defines the permissions for the target Itimer3.timer_cfg_vbp region 0 firewall.
  fields as TIFS_CBASS_FW_REGS_rom_fw_region_0_permission_0
0x14010 TIFS_CBASS_FW_REGS_timer2_cfg_vbp_fw_region_0_start_address_l access per field reset 0x44238000 — The FW Region 0 Start Address Low Register defines the start address bits 31 to 0 for the target Itimer3.timer_cfg_vbp region 0 firewall.
  fields as TIFS_CBASS_FW_REGS_rom_fw_region_0_start_address_l
0x14014 TIFS_CBASS_FW_REGS_timer2_cfg_vbp_fw_region_0_start_address_h — The FW Region 0 Start Address High Register defines the start address bits 47 to 32 for the target Itimer3.timer_cfg_vbp region 0 firewall.
  [15:0] START_ADDRESS_H — Start address bits 47 to 32.
0x14018 TIFS_CBASS_FW_REGS_timer2_cfg_vbp_fw_region_0_end_address_l access per field reset 0x44238FFF — The FW Region 0 End Address Low Register defines the end address bits 31 to 0 to include for the target Itimer3.timer_cfg_vbp region 0 firewall.
  fields as TIFS_CBASS_FW_REGS_rom_fw_region_0_end_address_l
0x1401C TIFS_CBASS_FW_REGS_timer2_cfg_vbp_fw_region_0_end_address_h — The FW Region 0 End Address High Register defines the end address bits 47 to 32 to include for the target Itimer3.timer_cfg_vbp region 0 firewall.
  fields as TIFS_CBASS_FW_REGS_rom_fw_region_0_end_address_h
0x14400 TIFS_CBASS_FW_REGS_timer3_cfg_vbp_fw_region_0_control access not given — The FW Region 0 Control Register defines the control fields for the target Itimer4.timer_cfg_vbp region 0 firewall.
  fields as TIFS_CBASS_FW_REGS_rom_fw_region_0_control
{0x14404+4i} TIFS_CBASS_FW_REGS_timer3_cfg_vbp_fw_region_0_permission_{i} (i=0..2) — The FW Region 0 Permission {i} Register defines the permissions for the target Itimer4.timer_cfg_vbp region 0 firewall.
  fields as TIFS_CBASS_FW_REGS_rom_fw_region_0_permission_0
0x14410 TIFS_CBASS_FW_REGS_timer3_cfg_vbp_fw_region_0_start_address_l access per field reset 0x44239000 — The FW Region 0 Start Address Low Register defines the start address bits 31 to 0 for the target Itimer4.timer_cfg_vbp region 0 firewall.
  fields as TIFS_CBASS_FW_REGS_rom_fw_region_0_start_address_l
0x14414 TIFS_CBASS_FW_REGS_timer3_cfg_vbp_fw_region_0_start_address_h — The FW Region 0 Start Address High Register defines the start address bits 47 to 32 for the target Itimer4.timer_cfg_vbp region 0 firewall.
  [15:0] START_ADDRESS_H — Start address bits 47 to 32.
0x14418 TIFS_CBASS_FW_REGS_timer3_cfg_vbp_fw_region_0_end_address_l access per field reset 0x44239FFF — The FW Region 0 End Address Low Register defines the end address bits 31 to 0 to include for the target Itimer4.timer_cfg_vbp region 0 firewall.
  fields as TIFS_CBASS_FW_REGS_rom_fw_region_0_end_address_l
0x1441C TIFS_CBASS_FW_REGS_timer3_cfg_vbp_fw_region_0_end_address_h — The FW Region 0 End Address High Register defines the end address bits 47 to 32 to include for the target Itimer4.timer_cfg_vbp region 0 firewall.
  fields as TIFS_CBASS_FW_REGS_rom_fw_region_0_end_address_h
0x16800 TIFS_CBASS_FW_REGS_Iaes_s_fw_region_0_control access not given — The FW Region 0 Control Register defines the control fields for the target Iaes.slv region 0 firewall.
  fields as TIFS_CBASS_FW_REGS_rom_fw_region_0_control
{0x16804+4i} TIFS_CBASS_FW_REGS_Iaes_s_fw_region_0_permission_{i} (i=0..2) — The FW Region 0 Permission {i} Register defines the permissions for the target Iaes.slv region 0 firewall.
  fields as TIFS_CBASS_FW_REGS_rom_fw_region_0_permission_0
0x16810 TIFS_CBASS_FW_REGS_Iaes_s_fw_region_0_start_address_l access per field reset 0x4423C000 — The FW Region 0 Start Address Low Register defines the start address bits 31 to 0 for the target Iaes.slv region 0 firewall.
  fields as TIFS_CBASS_FW_REGS_rom_fw_region_0_start_address_l
0x16814 TIFS_CBASS_FW_REGS_Iaes_s_fw_region_0_start_address_h — The FW Region 0 Start Address High Register defines the start address bits 47 to 32 for the target Iaes.slv region 0 firewall.
  [15:0] START_ADDRESS_H — Start address bits 47 to 32.
0x16818 TIFS_CBASS_FW_REGS_Iaes_s_fw_region_0_end_address_l access per field reset 0x4423DFFF — The FW Region 0 End Address Low Register defines the end address bits 31 to 0 to include for the target Iaes.slv region 0 firewall.
  fields as TIFS_CBASS_FW_REGS_rom_fw_region_0_end_address_l
0x1681C TIFS_CBASS_FW_REGS_Iaes_s_fw_region_0_end_address_h — The FW Region 0 End Address High Register defines the end address bits 47 to 32 to include for the target Iaes.slv region 0 firewall.
  fields as TIFS_CBASS_FW_REGS_rom_fw_region_0_end_address_h
0x16820 TIFS_CBASS_FW_REGS_Iaes_s_fw_region_1_control access not given — The FW Region 1 Control Register defines the control fields for the target Iaes.slv region 1 firewall.
  fields as TIFS_CBASS_FW_REGS_rom_fw_region_0_control
{0x16824+4i} TIFS_CBASS_FW_REGS_Iaes_s_fw_region_1_permission_{i} (i=0..2) — The FW Region 1 Permission {i} Register defines the permissions for the target Iaes.slv region 1 firewall.
  fields as TIFS_CBASS_FW_REGS_rom_fw_region_0_permission_0
0x16830 TIFS_CBASS_FW_REGS_Iaes_s_fw_region_1_start_address_l access per field — The FW Region 1 Start Address Low Register defines the start address bits 31 to 0 for the target Iaes.slv region 1 firewall.
  fields as TIFS_CBASS_FW_REGS_rom_fw_region_0_start_address_l
0x16834 TIFS_CBASS_FW_REGS_Iaes_s_fw_region_1_start_address_h — The FW Region 1 Start Address High Register defines the start address bits 47 to 32 for the target Iaes.slv region 1 firewall.
  [15:0] START_ADDRESS_H — Start address bits 47 to 32.
0x16838 TIFS_CBASS_FW_REGS_Iaes_s_fw_region_1_end_address_l access per field reset 0xFFF — The FW Region 1 End Address Low Register defines the end address bits 31 to 0 to include for the target Iaes.slv region 1 firewall.
  fields as TIFS_CBASS_FW_REGS_rom_fw_region_0_end_address_l
0x1683C TIFS_CBASS_FW_REGS_Iaes_s_fw_region_1_end_address_h — The FW Region 1 End Address High Register defines the end address bits 47 to 32 to include for the target Iaes.slv region 1 firewall.
  fields as TIFS_CBASS_FW_REGS_rom_fw_region_0_end_address_h
{0x1F800+0x20*i} TIFS_CBASS_FW_REGS_sms_dmss_hsm_fw_region_{i}_control access not given (i=0..23) — The FW Region {i} Control Register defines the control fields for the target sms_dmss_hsm.slv region {i} firewall.
  fields as TIFS_CBASS_FW_REGS_rom_fw_region_0_control
{0x1F804+0x20*i} TIFS_CBASS_FW_REGS_sms_dmss_hsm_fw_region_{i}_permission_0 (i=0..23) — The FW Region {i} Permission 0 Register defines the permissions for the target sms_dmss_hsm.slv region {i} firewall.
  fields as TIFS_CBASS_FW_REGS_rom_fw_region_0_permission_0
{0x1F808+0x20*i} TIFS_CBASS_FW_REGS_sms_dmss_hsm_fw_region_{i}_permission_1 (i=0..23) — The FW Region {i} Permission 1 Register defines the permissions for the target sms_dmss_hsm.slv region {i} firewall.
  fields as TIFS_CBASS_FW_REGS_rom_fw_region_0_permission_0
{0x1F80C+0x20*i} TIFS_CBASS_FW_REGS_sms_dmss_hsm_fw_region_{i}_permission_2 (i=0..23) — The FW Region {i} Permission 2 Register defines the permissions for the target sms_dmss_hsm.slv region {i} firewall.
  fields as TIFS_CBASS_FW_REGS_rom_fw_region_0_permission_0
0x1F810 TIFS_CBASS_FW_REGS_sms_dmss_hsm_fw_region_0_start_address_l access per field reset 0x44800000 — The FW Region 0 Start Address Low Register defines the start address bits 31 to 0 for the target sms_dmss_hsm.slv region 0 firewall.
  fields as TIFS_CBASS_FW_REGS_rom_fw_region_0_start_address_l
{0x1F814+0x20*i} TIFS_CBASS_FW_REGS_sms_dmss_hsm_fw_region_{i}_start_address_h (i=0..23) — The FW Region {i} Start Address High Register defines the start address bits 47 to 32 for the target sms_dmss_hsm.slv region {i} firewall.
  [15:0] START_ADDRESS_H — Start address bits 47 to 32.
0x1F818 TIFS_CBASS_FW_REGS_sms_dmss_hsm_fw_region_0_end_address_l access per field reset 0x44FFFFFF — The FW Region 0 End Address Low Register defines the end address bits 31 to 0 to include for the target sms_dmss_hsm.slv region 0 firewall.
  fields as TIFS_CBASS_FW_REGS_rom_fw_region_0_end_address_l
{0x1F81C+0x20*i} TIFS_CBASS_FW_REGS_sms_dmss_hsm_fw_region_{i}_end_address_h (i=0..23) — The FW Region {i} End Address High Register defines the end address bits 47 to 32 to include for the target sms_dmss_hsm.slv region {i} firewall.
  fields as TIFS_CBASS_FW_REGS_rom_fw_region_0_end_address_h
0x1F830 TIFS_CBASS_FW_REGS_sms_dmss_hsm_fw_region_1_start_address_l access per field reset 0x43702000 — The FW Region 1 Start Address Low Register defines the start address bits 31 to 0 for the target sms_dmss_hsm.slv region 1 firewall.
  fields as TIFS_CBASS_FW_REGS_rom_fw_region_0_start_address_l
0x1F838 TIFS_CBASS_FW_REGS_sms_dmss_hsm_fw_region_1_end_address_l access per field reset 0x43702FFF — The FW Region 1 End Address Low Register defines the end address bits 31 to 0 to include for the target sms_dmss_hsm.slv region 1 firewall.
  fields as TIFS_CBASS_FW_REGS_rom_fw_region_0_end_address_l
{0x1F810+0x20*i} TIFS_CBASS_FW_REGS_sms_dmss_hsm_fw_region_{i}_start_address_l access per field (i=2..23) — The FW Region {i} Start Address Low Register defines the start address bits 31 to 0 for the target sms_dmss_hsm.slv region {i} firewall.
  fields as TIFS_CBASS_FW_REGS_rom_fw_region_0_start_address_l
{0x1F818+0x20*i} TIFS_CBASS_FW_REGS_sms_dmss_hsm_fw_region_{i}_end_address_l access per field reset 0xFFF (i=2..23) — The FW Region {i} End Address Low Register defines the end address bits 31 to 0 to include for the target sms_dmss_hsm.slv region {i} firewall.
  fields as TIFS_CBASS_FW_REGS_rom_fw_region_0_end_address_l
{0x1FC00+0x20*i} TIFS_CBASS_FW_REGS_Ifwmgr_m_fw_region_{i}_control access not given (i=0..7) — The FW Region {i} Control Register defines the control fields for the target Ifwmgr_int.slv region {i} firewall.
  fields as TIFS_CBASS_FW_REGS_rom_fw_region_0_control
{0x1FC04+0x20*i} TIFS_CBASS_FW_REGS_Ifwmgr_m_fw_region_{i}_permission_0 (i=0..7) — The FW Region {i} Permission 0 Register defines the permissions for the target Ifwmgr_int.slv region {i} firewall.
  fields as TIFS_CBASS_FW_REGS_rom_fw_region_0_permission_0
{0x1FC08+0x20*i} TIFS_CBASS_FW_REGS_Ifwmgr_m_fw_region_{i}_permission_1 (i=0..7) — The FW Region {i} Permission 1 Register defines the permissions for the target Ifwmgr_int.slv region {i} firewall.
  fields as TIFS_CBASS_FW_REGS_rom_fw_region_0_permission_0
{0x1FC0C+0x20*i} TIFS_CBASS_FW_REGS_Ifwmgr_m_fw_region_{i}_permission_2 (i=0..7) — The FW Region {i} Permission 2 Register defines the permissions for the target Ifwmgr_int.slv region {i} firewall.
  fields as TIFS_CBASS_FW_REGS_rom_fw_region_0_permission_0
0x1FC10 TIFS_CBASS_FW_REGS_Ifwmgr_m_fw_region_0_start_address_l access per field reset 0x45000000 — The FW Region 0 Start Address Low Register defines the start address bits 31 to 0 for the target Ifwmgr_int.slv region 0 firewall.
  fields as TIFS_CBASS_FW_REGS_rom_fw_region_0_start_address_l
{0x1FC14+0x20*i} TIFS_CBASS_FW_REGS_Ifwmgr_m_fw_region_{i}_start_address_h (i=0..7) — The FW Region {i} Start Address High Register defines the start address bits 47 to 32 for the target Ifwmgr_int.slv region {i} firewall.
  [15:0] START_ADDRESS_H — Start address bits 47 to 32.
0x1FC18 TIFS_CBASS_FW_REGS_Ifwmgr_m_fw_region_0_end_address_l access per field reset 0x45FFFFFF — The FW Region 0 End Address Low Register defines the end address bits 31 to 0 to include for the target Ifwmgr_int.slv region 0 firewall.
  fields as TIFS_CBASS_FW_REGS_rom_fw_region_0_end_address_l
{0x1FC1C+0x20*i} TIFS_CBASS_FW_REGS_Ifwmgr_m_fw_region_{i}_end_address_h (i=0..7) — The FW Region {i} End Address High Register defines the end address bits 47 to 32 to include for the target Ifwmgr_int.slv region {i} firewall.
  fields as TIFS_CBASS_FW_REGS_rom_fw_region_0_end_address_h
{0x1FC10+0x20*i} TIFS_CBASS_FW_REGS_Ifwmgr_m_fw_region_{i}_start_address_l access per field (i=1..7) — The FW Region {i} Start Address Low Register defines the start address bits 31 to 0 for the target Ifwmgr_int.slv region {i} firewall.
  fields as TIFS_CBASS_FW_REGS_rom_fw_region_0_start_address_l
{0x1FC18+0x20*i} TIFS_CBASS_FW_REGS_Ifwmgr_m_fw_region_{i}_end_address_l access per field reset 0xFFF (i=1..7) — The FW Region {i} End Address Low Register defines the end address bits 31 to 0 to include for the target Ifwmgr_int.slv region {i} firewall.
  fields as TIFS_CBASS_FW_REGS_rom_fw_region_0_end_address_l
